VERSION ""

NS_ :

BS_:

BU_: CUSTOMER_ECU PACMOD

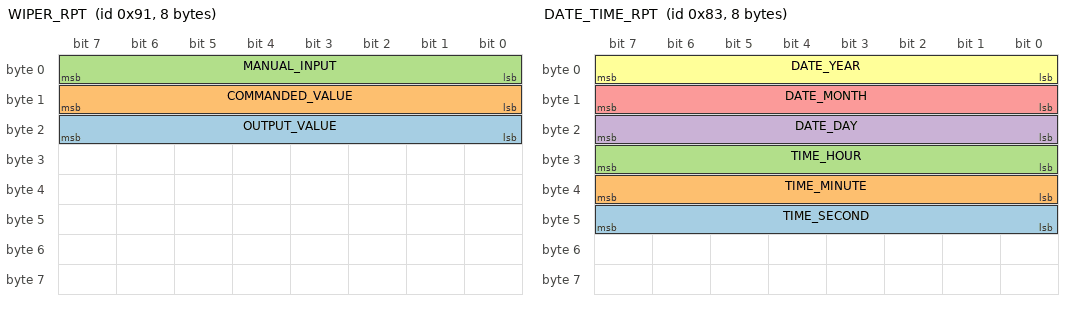
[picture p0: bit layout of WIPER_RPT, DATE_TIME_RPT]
BO_ 145 WIPER_RPT: 8 PACMOD
 SG_ OUTPUT_VALUE : 23|8@0+ (1,0) [0|7] ""  CUSTOMER_ECU
 SG_ COMMANDED_VALUE : 15|8@0+ (1,0) [0|7] ""  CUSTOMER_ECU
 SG_ MANUAL_INPUT : 7|8@0+ (1,0) [0|7] ""  CUSTOMER_ECU

BO_ 144 WIPER_CMD: 8 CUSTOMER_ECU
 SG_ WIPER_CMD : 7|8@0+ (1,0) [0|7] ""  PACMOD

BO_ 132 STEERING_PID_RPT_4: 8 PACMOD

BO_ 131 DATE_TIME_RPT: 8 PACMOD
 SG_ TIME_SECOND : 47|8@0+ (1,0) [0|60] "sec"  CUSTOMER_ECU
 SG_ TIME_MINUTE : 39|8@0+ (1,0) [0|60] "min"  CUSTOMER_ECU
 SG_ TIME_HOUR : 31|8@0+ (1,0) [0|23] "hr"  CUSTOMER_ECU
 SG_ DATE_DAY : 23|8@0+ (1,1) [1|31] "dy"  CUSTOMER_ECU
 SG_ DATE_MONTH : 15|8@0+ (1,1) [1|12] "mon"  CUSTOMER_ECU
 SG_ DATE_YEAR : 7|8@0+ (1,2000) [2000|2255] "yr"  CUSTOMER_ECU

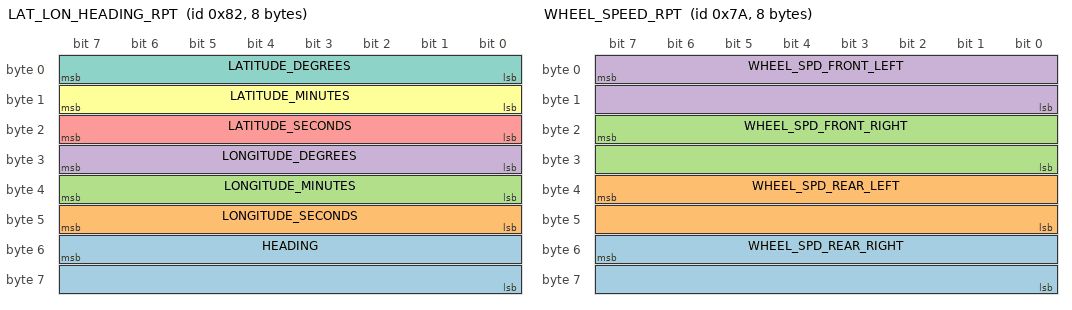
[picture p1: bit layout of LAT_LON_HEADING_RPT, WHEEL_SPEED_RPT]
BO_ 130 LAT_LON_HEADING_RPT: 8 PACMOD
 SG_ HEADING : 55|16@0- (0.01,0) [-327.68|327.67] "deg"  CUSTOMER_ECU
 SG_ LONGITUDE_SECONDS : 47|8@0- (1,0) [-128|127] "sec"  CUSTOMER_ECU
 SG_ LONGITUDE_MINUTES : 39|8@0- (1,0) [-128|127] "min"  CUSTOMER_ECU
 SG_ LONGITUDE_DEGREES : 31|8@0- (1,0) [-128|127] "deg"  CUSTOMER_ECU
 SG_ LATITUDE_SECONDS : 23|8@0- (1,0) [-128|127] "sec"  CUSTOMER_ECU
 SG_ LATITUDE_MINUTES : 15|8@0- (1,0) [-128|127] "min"  CUSTOMER_ECU
 SG_ LATITUDE_DEGREES : 7|8@0- (1,0) [-128|127] "deg"  CUSTOMER_ECU

BO_ 129 YAW_RATE_RPT: 8 PACMOD
 SG_ YAW_RATE : 7|16@0- (0.01,0) [-327.68|327.67] "rad/s"  CUSTOMER_ECU

BO_ 128 PARKING_BRAKE_STATUS_RPT: 8 PACMOD
 SG_ PARKING_BRAKE_ENABLED : 0|1@0+ (1,0) [0|1] ""  CUSTOMER_ECU

BO_ 127 STEERING_RPT_3: 8 PACMOD

BO_ 126 STEERING_RPT_2: 8 PACMOD

BO_ 125 STEERING_PID_RPT_3: 8 PACMOD

BO_ 124 STEERING_PID_RPT_2: 8 PACMOD

BO_ 123 STEERING_PID_RPT_1: 8 PACMOD

BO_ 122 WHEEL_SPEED_RPT: 8 PACMOD
 SG_ WHEEL_SPD_REAR_RIGHT : 55|16@0- (1,0) [-32768|32767] "rad/s"  CUSTOMER_ECU
 SG_ WHEEL_SPD_REAR_LEFT : 39|16@0- (1,0) [-32768|32767] "rad/s"  CUSTOMER_ECU
 SG_ WHEEL_SPD_FRONT_RIGHT : 23|16@0- (1,0) [-32768|32767] "rad/s"  CUSTOMER_ECU
 SG_ WHEEL_SPD_FRONT_LEFT : 7|16@0- (1,0) [-32768|32767] "rad/s"  CUSTOMER_ECU

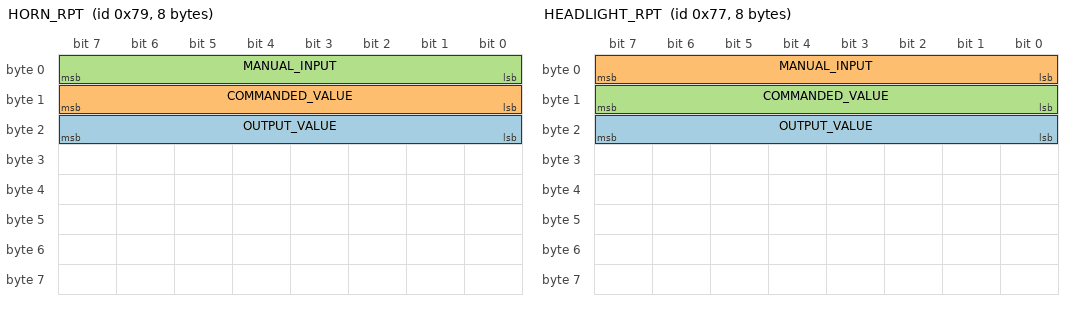
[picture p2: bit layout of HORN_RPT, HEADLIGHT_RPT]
BO_ 121 HORN_RPT: 8 PACMOD
 SG_ OUTPUT_VALUE : 23|8@0+ (1,0) [0|1] ""  CUSTOMER_ECU
 SG_ COMMANDED_VALUE : 15|8@0+ (1,0) [0|1] ""  CUSTOMER_ECU
 SG_ MANUAL_INPUT : 7|8@0+ (1,0) [0|1] ""  CUSTOMER_ECU

BO_ 120 HORN_CMD: 8 CUSTOMER_ECU
 SG_ HORN_CMD : 7|8@0+ (1,0) [0|1] ""  PACMOD

BO_ 119 HEADLIGHT_RPT: 8 PACMOD
 SG_ OUTPUT_VALUE : 23|8@0+ (1,0) [0|2] ""  CUSTOMER_ECU
 SG_ MANUAL_INPUT : 7|8@0+ (1,0) [0|2] ""  CUSTOMER_ECU
 SG_ COMMANDED_VALUE : 15|8@0+ (1,0) [0|2] ""  CUSTOMER_ECU

BO_ 118 HEADLIGHT_CMD: 8 CUSTOMER_ECU
 SG_ HEADLIGHT_CMD : 7|8@0+ (1,0) [0|2] ""  PACMOD

BO_ 99 TURN_CMD: 8 CUSTOMER_ECU
 SG_ TURN_SIGNAL_CMD : 7|8@0+ (1,0) [0|3] ""  PACMOD

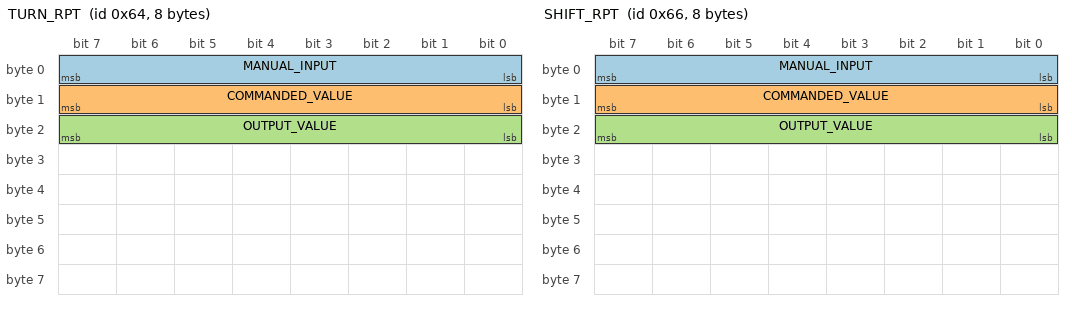
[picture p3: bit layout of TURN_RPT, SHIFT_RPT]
BO_ 100 TURN_RPT: 8 PACMOD
 SG_ MANUAL_INPUT : 7|8@0+ (1,0) [0|3] ""  CUSTOMER_ECU
 SG_ COMMANDED_VALUE : 15|8@0+ (1,0) [0|3] ""  CUSTOMER_ECU
 SG_ OUTPUT_VALUE : 23|8@0+ (1,0) [0|3] ""  CUSTOMER_ECU

BO_ 101 SHIFT_CMD: 8 CUSTOMER_ECU
 SG_ SHIFT_CMD : 7|8@0+ (1,0) [0|4] ""  PACMOD

BO_ 102 SHIFT_RPT: 8 PACMOD
 SG_ MANUAL_INPUT : 7|8@0+ (1,0) [0|4] ""  CUSTOMER_ECU
 SG_ COMMANDED_VALUE : 15|8@0+ (1,0) [0|4] ""  CUSTOMER_ECU
 SG_ OUTPUT_VALUE : 23|8@0+ (1,0) [0|4] ""  CUSTOMER_ECU

BO_ 103 ACCEL_CMD: 8 CUSTOMER_ECU
 SG_ ACCEL_CMD : 7|16@0+ (0.001,0) [0|1] "%"  PACMOD

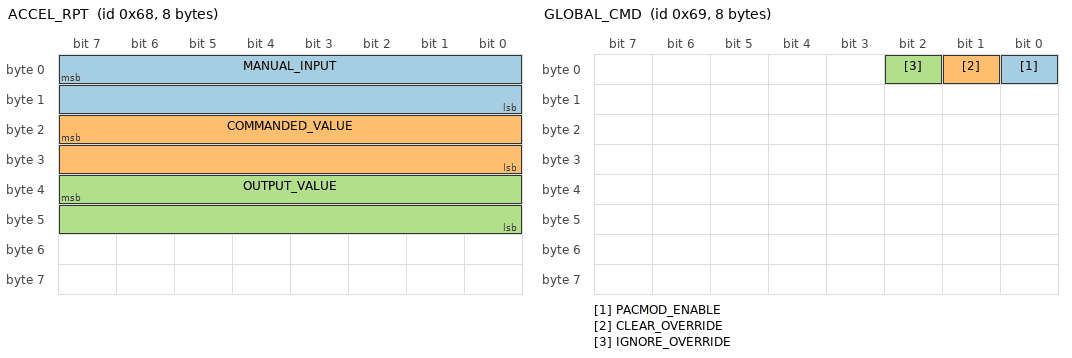
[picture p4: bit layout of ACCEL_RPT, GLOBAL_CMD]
BO_ 104 ACCEL_RPT: 8 PACMOD
 SG_ MANUAL_INPUT : 7|16@0+ (0.001,0) [0|1] "%"  CUSTOMER_ECU
 SG_ COMMANDED_VALUE : 23|16@0+ (0.001,0) [0|1] "%"  CUSTOMER_ECU
 SG_ OUTPUT_VALUE : 39|16@0+ (0.001,0) [0|1] "%"  CUSTOMER_ECU

BO_ 105 GLOBAL_CMD: 8 CUSTOMER_ECU
 SG_ PACMOD_ENABLE : 0|1@0+ (1,0) [0|1] ""  PACMOD
 SG_ CLEAR_OVERRIDE : 1|1@0+ (1,0) [0|1] ""  PACMOD
 SG_ IGNORE_OVERRIDE : 2|1@0+ (1,0) [0|1] ""  PACMOD

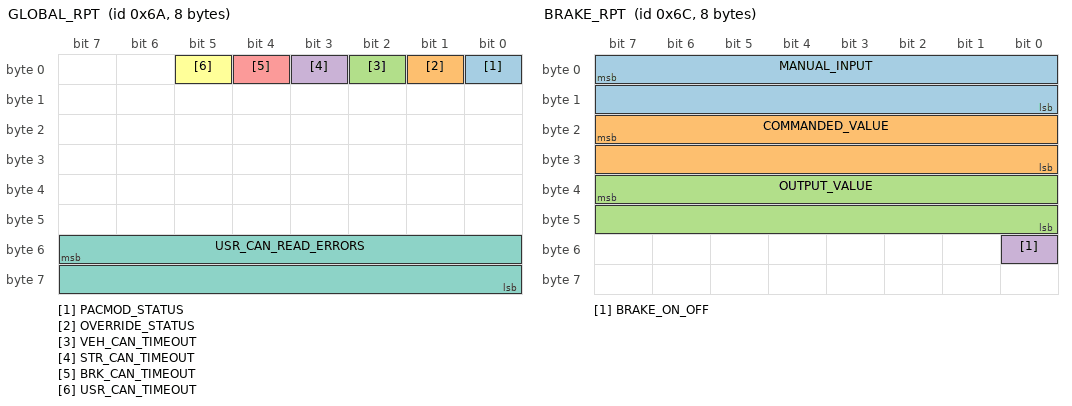
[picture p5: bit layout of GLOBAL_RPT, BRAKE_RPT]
BO_ 106 GLOBAL_RPT: 8 PACMOD
 SG_ PACMOD_STATUS : 0|1@0+ (1,0) [0|1] ""  CUSTOMER_ECU
 SG_ OVERRIDE_STATUS : 1|1@0+ (1,0) [0|1] ""  CUSTOMER_ECU
 SG_ VEH_CAN_TIMEOUT : 2|1@0+ (1,0) [0|1] ""  CUSTOMER_ECU
 SG_ STR_CAN_TIMEOUT : 3|1@0+ (1,0) [0|1] ""  CUSTOMER_ECU
 SG_ BRK_CAN_TIMEOUT : 4|1@0+ (1,0) [0|1] ""  CUSTOMER_ECU
 SG_ USR_CAN_TIMEOUT : 5|1@0+ (1,0) [0|1] ""  CUSTOMER_ECU
 SG_ USR_CAN_READ_ERRORS : 55|16@0+ (1,0) [0|65535] ""  CUSTOMER_ECU

BO_ 107 BRAKE_CMD: 8 CUSTOMER_ECU
 SG_ BRAKE_CMD : 7|16@0+ (0.001,0) [0|1] "%"  PACMOD

BO_ 108 BRAKE_RPT: 8 PACMOD
 SG_ MANUAL_INPUT : 7|16@0+ (0.001,0) [0|1] "%"  CUSTOMER_ECU
 SG_ COMMANDED_VALUE : 23|16@0+ (0.001,0) [0|1] "%"  CUSTOMER_ECU
 SG_ OUTPUT_VALUE : 39|16@0+ (0.001,0) [0|1] "%"  CUSTOMER_ECU
 SG_ BRAKE_ON_OFF : 48|1@0+ (1,0) [0|1] ""  CUSTOMER_ECU

BO_ 109 STEERING_CMD: 8 CUSTOMER_ECU
 SG_ POSITION_VALUE : 7|32@0- (0.001,0) [-12|12] "radians"  PACMOD
 SG_ SPEED_LIMIT : 39|32@0+ (0.001,0) [0|4294967.295] "rad/s"  PACMOD

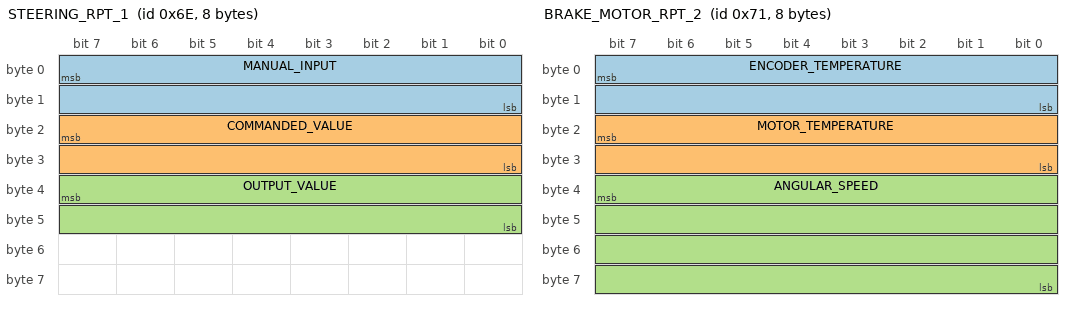
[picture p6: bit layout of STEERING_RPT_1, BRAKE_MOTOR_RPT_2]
BO_ 110 STEERING_RPT_1: 8 PACMOD
 SG_ MANUAL_INPUT : 7|16@0- (0.001,0) [-32.768|32.767] "rad/s"  CUSTOMER_ECU
 SG_ COMMANDED_VALUE : 23|16@0- (0.001,0) [-32.768|32.767] "rad/s"  CUSTOMER_ECU
 SG_ OUTPUT_VALUE : 39|16@0- (0.001,0) [-32.768|32.767] "rad/s"  CUSTOMER_ECU

BO_ 111 VEHICLE_SPEED_RPT: 8 PACMOD
 SG_ VEHICLE_SPEED : 7|16@0- (0.01,0) [-327.68|327.67] "m/s"  CUSTOMER_ECU
 SG_ VEHICLE_SPEED_VALID : 16|1@0+ (1,0) [0|1] ""  CUSTOMER_ECU

BO_ 112 BRAKE_MOTOR_RPT_1: 8 PACMOD
 SG_ MOTOR_CURRENT : 7|32@0+ (0.001,0) [0|4294967.295] "amps"  CUSTOMER_ECU
 SG_ SHAFT_POSITION : 39|32@0- (0.001,0) [-2147483.648|2147483.647] "radians"  CUSTOMER_ECU

BO_ 113 BRAKE_MOTOR_RPT_2: 8 PACMOD
 SG_ ENCODER_TEMPERATURE : 7|16@0- (1,-40) [-32808|32727] "deg_C"  CUSTOMER_ECU
 SG_ MOTOR_TEMPERATURE : 23|16@0- (1,-40) [-32808|32727] "deg_C"  CUSTOMER_ECU
 SG_ ANGULAR_SPEED : 39|32@0+ (0.001,0) [0|4294967.295] "rev/s"  CUSTOMER_ECU

BO_ 114 BRAKE_MOTOR_RPT_3: 8 PACMOD
 SG_ TORQUE_OUTPUT : 7|32@0- (0.001,0) [-2147483.648|2147483.647] "N-m"  CUSTOMER_ECU
 SG_ TORQUE_INPUT : 39|32@0- (0.001,0) [-2147483.648|2147483.647] "N-m"  CUSTOMER_ECU

BO_ 115 STEERING_MOTOR_RPT_1: 8 PACMOD
 SG_ MOTOR_CURRENT : 7|32@0+ (0.001,0) [0|4294967.295] "amps"  CUSTOMER_ECU
 SG_ SHAFT_POSITION : 39|32@0- (0.001,0) [-2147483.648|2147483.647] "amps"  CUSTOMER_ECU

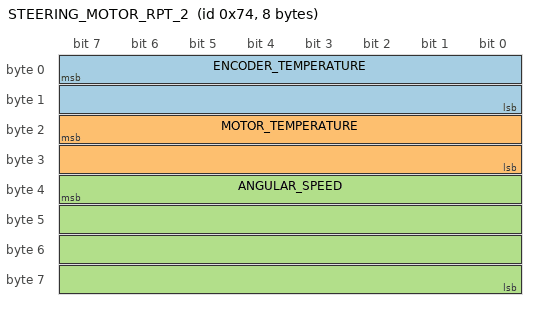
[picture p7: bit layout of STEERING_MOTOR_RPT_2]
BO_ 116 STEERING_MOTOR_RPT_2: 8 PACMOD
 SG_ ENCODER_TEMPERATURE : 7|16@0- (1,-40) [-32808|32727] "deg_C"  CUSTOMER_ECU
 SG_ MOTOR_TEMPERATURE : 23|16@0- (1,-40) [-32808|32727] "deg_C"  CUSTOMER_ECU
 SG_ ANGULAR_SPEED : 39|32@0- (0.001,0) [-2147483.648|2147483.647] "rev/s"  CUSTOMER_ECU

BO_ 117 STEERING_MOTOR_RPT_3: 8 PACMOD
 SG_ TORQUE_OUTPUT : 7|32@0- (0.001,0) [-2147483.648|2147483.647] "N-m"  CUSTOMER_ECU
 SG_ TORQUE_INPUT : 39|32@0- (0.001,0) [-2147483.648|2147483.647] "N-m"  CUSTOMER_ECU

CM_ BU_ PACMOD "AutonomouStuff PACMod";
CM_ SG_ 101 SHIFT_CMD "FORWARD_is_also_LOW_on_vehicles_with_LOW/HIGH,_PARK_and_HIGH_only_available_on_certain_Vehicles";
VAL_ 145 OUTPUT_VALUE 7 "High" 6 "Low" 5 "Intermittent 5" 4 "Intermittent 4" 3 "Intermittent 3" 2 "Intermittent 2" 1 "Intermittent 1" 0 "Wipers Off" ;
VAL_ 145 COMMANDED_VALUE 7 "High" 6 "Low" 5 "Intermittent 5" 4 "Intermittent 4" 3 "Intermittent 3" 2 "Intermittent 2" 1 "Intermittent 1" 0 "Wipers Off" ;
VAL_ 145 MANUAL_INPUT 7 "High" 6 "Low" 5 "Intermittent 5" 4 "Intermittent 4" 3 "Intermittent 3" 2 "Intermittent 2" 1 "Intermittent 1" 0 "Wipers Off" ;
VAL_ 144 WIPER_CMD 7 "High" 6 "Low" 5 "Intermittent 5" 4 "Intermittent 4" 3 "Intermittent 3" 2 "Intermittent 2" 1 "Intermittent 1" 0 "Wipers Off" ;
VAL_ 128 PARKING_BRAKE_ENABLED 0 "OFF" 1 "ON" ;
VAL_ 121 OUTPUT_VALUE 0 "OFF" 1 "ON" ;
VAL_ 121 COMMANDED_VALUE 0 "OFF" 1 "ON" ;
VAL_ 121 MANUAL_INPUT 0 "OFF" 1 "ON" ;
VAL_ 120 HORN_CMD 0 "OFF" 1 "ON" ;
VAL_ 119 OUTPUT_VALUE 2 "High Beams" 1 "Low Beams" 0 "Headlights Off" ;
VAL_ 119 MANUAL_INPUT 2 "High Beams" 1 "Low Beams" 0 "Headlights Off" ;
VAL_ 119 COMMANDED_VALUE 2 "High Beams" 1 "Low Beams" 0 "Headlights Off" ;
VAL_ 118 HEADLIGHT_CMD 2 "High Beams" 1 "Low Beams" 0 "Headlights Off" ;
VAL_ 99 TURN_SIGNAL_CMD 0 "RIGHT" 1 "NONE" 2 "LEFT" 3 "HAZARD" ;
VAL_ 100 MANUAL_INPUT 0 "RIGHT" 1 "NONE" 2 "LEFT" 3 "HAZARD" ;
VAL_ 100 COMMANDED_VALUE 0 "RIGHT" 1 "NONE" 2 "LEFT" 3 "HAZARD" ;
VAL_ 100 OUTPUT_VALUE 0 "RIGHT" 1 "NONE" 2 "LEFT" 3 "HAZARD" ;
VAL_ 101 SHIFT_CMD 0 "PARK" 1 "REVERSE" 2 "NEUTRAL" 3 "FORWARD" 4 "LOW" ;
VAL_ 102 MANUAL_INPUT 0 "PARK" 1 "REVERSE" 2 "NEUTRAL" 3 "FORWARD" 4 "HIGH" ;
VAL_ 102 COMMANDED_VALUE 0 "PARK" 1 "REVERSE" 2 "NEUTRAL" 3 "FORWARD" 4 "HIGH" ;
VAL_ 102 OUTPUT_VALUE 0 "PARK" 1 "REVERSE" 2 "NEUTRAL" 3 "FORWARD" 4 "HIGH" ;
VAL_ 105 PACMOD_ENABLE 0 "Control Disabled" 1 "Control Enabled" ;
VAL_ 105 CLEAR_OVERRIDE 0 "Don't Clear Active Overrides" 1 "Clear Active Overrides" ;
VAL_ 105 IGNORE_OVERRIDE 0 "Don't Ignore User Overrides" 1 "Ignore User Overrides" ;
VAL_ 106 PACMOD_STATUS 0 "Control Disabled" 1 "Control Enabled" ;
VAL_ 106 OVERRIDE_STATUS 0 "Not Overridden" 1 "Overridden" ;
VAL_ 106 BRK_CAN_TIMEOUT 0 "No Active CAN Timeout" 1 "Active CAN Timeout" ;
VAL_ 108 BRAKE_ON_OFF 0 "OFF" 1 "ON" ;
VAL_ 111 VEHICLE_SPEED_VALID 0 "INVALID" 1 "VALID" ;
